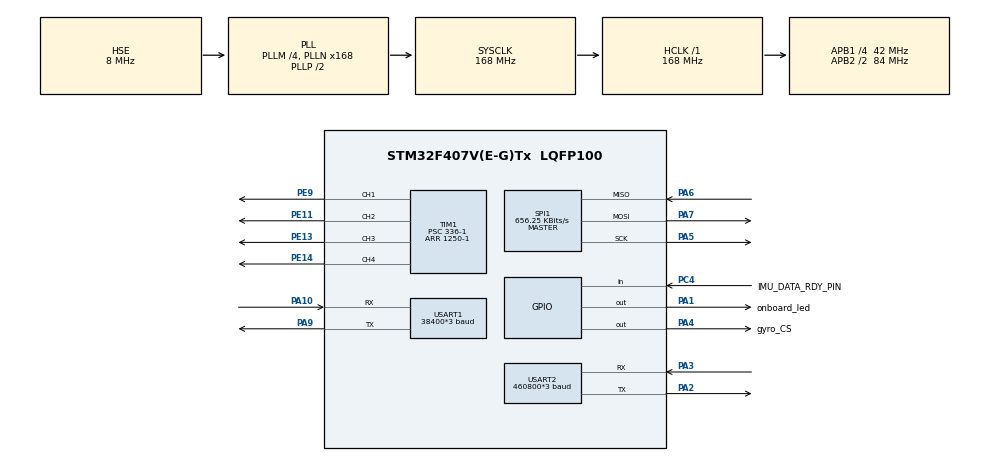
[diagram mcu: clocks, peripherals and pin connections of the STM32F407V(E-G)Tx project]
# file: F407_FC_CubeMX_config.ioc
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Dma.Request0=SPI1_RX
Dma.Request1=SPI1_TX
Dma.Request2=USART1_TX
Dma.SPI1_RX.0.Direction=DMA_PERIPH_TO_MEMORY
Dma.SPI1_RX.0.FIFOMode=DMA_FIFOMODE_DISABLE
Dma.SPI1_RX.0.Instance=DMA2_Stream2
Dma.SPI1_RX.0.MemDataAlignment=DMA_MDATAALIGN_BYTE
Dma.SPI1_RX.0.MemInc=DMA_MINC_ENABLE
Dma.SPI1_RX.0.Mode=DMA_NORMAL
Dma.SPI1_RX.0.PeriphDataAlignment=DMA_PDATAALIGN_BYTE
Dma.SPI1_RX.0.PeriphInc=DMA_PINC_DISABLE
Dma.SPI1_RX.0.Priority=DMA_PRIORITY_LOW
Dma.SPI1_TX.1.Direction=DMA_MEMORY_TO_PERIPH
Dma.SPI1_TX.1.FIFOMode=DMA_FIFOMODE_DISABLE
Dma.SPI1_TX.1.Instance=DMA2_Stream3
Dma.SPI1_TX.1.MemDataAlignment=DMA_MDATAALIGN_BYTE
Dma.SPI1_TX.1.MemInc=DMA_MINC_ENABLE
Dma.SPI1_TX.1.Mode=DMA_NORMAL
Dma.SPI1_TX.1.PeriphDataAlignment=DMA_PDATAALIGN_BYTE
Dma.SPI1_TX.1.PeriphInc=DMA_PINC_DISABLE
Dma.SPI1_TX.1.Priority=DMA_PRIORITY_LOW
Dma.USART1_TX.2.Direction=DMA_MEMORY_TO_PERIPH
Dma.USART1_TX.2.FIFOMode=DMA_FIFOMODE_DISABLE
Dma.USART1_TX.2.Instance=DMA2_Stream7
Dma.USART1_TX.2.MemDataAlignment=DMA_MDATAALIGN_BYTE
Dma.USART1_TX.2.MemInc=DMA_MINC_ENABLE
Dma.USART1_TX.2.Mode=DMA_NORMAL
Dma.USART1_TX.2.PeriphDataAlignment=DMA_PDATAALIGN_BYTE
Dma.USART1_TX.2.PeriphInc=DMA_PINC_DISABLE
Dma.USART1_TX.2.Priority=DMA_PRIORITY_LOW
Mcu.Family=STM32F4
Mcu.Name=STM32F407V(E-G)Tx
Mcu.Package=LQFP100
NVIC.DMA2_Stream2_IRQn=true\:0\:0\:false\:false\:true\:false\:true\:true
NVIC.DMA2_Stream3_IRQn=true\:0\:0\:false\:false\:true\:false\:true\:true
NVIC.DMA2_Stream7_IRQn=true\:0\:0\:false\:false\:true\:false\:true\:true
NVIC.PriorityGroup=NVIC_PRIORITYGROUP_4
NVIC.SPI1_IRQn=true\:0\:0\:false\:false\:true\:true\:true\:true
NVIC.TIM6_DAC_IRQn=true\:0\:0\:false\:false\:true\:true\:true\:true
NVIC.TIM7_IRQn=true\:0\:0\:false\:false\:true\:true\:true\:true
NVIC.USART2_IRQn=true\:0\:0\:false\:false\:true\:true\:true\:true
PA1.GPIO_Label=onboard_led
PA1.GPIO_PuPd=GPIO_PULLUP
PA1.PinState=GPIO_PIN_SET
PA1.Signal=GPIO_Output
PA10.Mode=Asynchronous
PA10.Signal=USART1_RX
PA13.Mode=Serial_Wire
PA13.Signal=SYS_JTMS-SWDIO
PA14.Mode=Serial_Wire
PA14.Signal=SYS_JTCK-SWCLK
PA2.Mode=Asynchronous
PA2.Signal=USART2_TX
PA3.Mode=Asynchronous
PA3.Signal=USART2_RX
PA4.GPIO_Label=gyro_CS
PA4.PinState=GPIO_PIN_SET
PA4.Signal=GPIO_Output
PA5.Mode=Full_Duplex_Master
PA5.Signal=SPI1_SCK
PA6.Mode=Full_Duplex_Master
PA6.Signal=SPI1_MISO
PA7.Mode=Full_Duplex_Master
PA7.Signal=SPI1_MOSI
PA9.Mode=Asynchronous
PA9.Signal=USART1_TX
PC14-OSC32_IN.Mode=LSE-External-Oscillator
PC14-OSC32_IN.Signal=RCC_OSC32_IN
PC15-OSC32_OUT.Mode=LSE-External-Oscillator
PC15-OSC32_OUT.Signal=RCC_OSC32_OUT
PC4.GPIO_Label=IMU_DATA_RDY_PIN
PC4.Signal=GPIO_Input
PE11.Signal=S_TIM1_CH2
PE13.Signal=S_TIM1_CH3
PE14.Signal=S_TIM1_CH4
PE9.Signal=S_TIM1_CH1
PH0-OSC_IN.Mode=HSE-External-Oscillator
PH0-OSC_IN.Signal=RCC_OSC_IN
PH1-OSC_OUT.Mode=HSE-External-Oscillator
PH1-OSC_OUT.Signal=RCC_OSC_OUT
ProjectManager.HeapSize=0x200
ProjectManager.StackSize=0x400
ProjectManager.TargetToolchain=CMake
RCC.48MHZClocksFreq_Value=84000000
RCC.AHBFreq_Value=168000000
RCC.APB1CLKDivider=RCC_HCLK_DIV4
RCC.APB1Freq_Value=42000000
RCC.APB1TimFreq_Value=84000000
RCC.APB2CLKDivider=RCC_HCLK_DIV2
RCC.APB2Freq_Value=84000000
RCC.APB2TimFreq_Value=168000000
RCC.CortexFreq_Value=168000000
RCC.HCLKFreq_Value=168000000
RCC.HSE_VALUE=8000000
RCC.HSI_VALUE=16000000
RCC.PLLM=4
RCC.PLLN=168
RCC.PLLSourceVirtual=RCC_PLLSOURCE_HSE
RCC.SYSCLKFreq_VALUE=168000000
RCC.SYSCLKSource=RCC_SYSCLKSOURCE_PLLCLK
RCC.VCOOutputFreq_Value=336000000
SH.S_TIM1_CH1.0=TIM1_CH1,PWM Generation1 CH1
SH.S_TIM1_CH2.0=TIM1_CH2,PWM Generation2 CH2
SH.S_TIM1_CH3.0=TIM1_CH3,PWM Generation3 CH3
SH.S_TIM1_CH4.0=TIM1_CH4,PWM Generation4 CH4
SPI1.BaudRatePrescaler=SPI_BAUDRATEPRESCALER_128
SPI1.CalculateBaudRate=656.25 KBits/s
SPI1.Direction=SPI_DIRECTION_2LINES
SPI1.Mode=SPI_MODE_MASTER
SPI1.TIMode=SPI_TIMODE_DISABLE
SPI1.VirtualType=VM_MASTER
TIM1.Channel-PWM\ Generation1\ CH1=TIM_CHANNEL_1
TIM1.Channel-PWM\ Generation2\ CH2=TIM_CHANNEL_2
TIM1.Channel-PWM\ Generation3\ CH3=TIM_CHANNEL_3
TIM1.Channel-PWM\ Generation4\ CH4=TIM_CHANNEL_4
TIM1.Period=1250-1
TIM1.Prescaler=336-1
TIM1.Pulse-PWM\ Generation1\ CH1=500
TIM1.Pulse-PWM\ Generation2\ CH2=500
TIM1.Pulse-PWM\ Generation3\ CH3=500
TIM1.Pulse-PWM\ Generation4\ CH4=500
TIM6.Period=10000-1
TIM6.Prescaler=8400-1
TIM7.Period=52500-1
TIM7.Prescaler=4-1
USART1.BaudRate=38400*3
USART1.VirtualMode=VM_ASYNC
USART2.BaudRate=460800*3
USART2.VirtualMode=VM_ASYNC
VP_TIM1_VS_ClockSourceINT.Mode=Internal
VP_TIM6_VS_ClockSourceINT.Mode=Enable_Timer
VP_TIM7_VS_ClockSourceINT.Mode=Enable_Timer
board=custom

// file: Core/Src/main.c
/* USER CODE BEGIN Header */
/**
 ******************************************************************************
 * @file           : main.c
 * @brief          : Main program body
 ******************************************************************************
 * @attention
 *
 * Copyright (c) 2023 STMicroelectronics.
 * All rights reserved.
 *
 * This software is licensed under terms that can be found in the LICENSE file
 * in the root directory of this software component.
 * If no LICENSE file comes with this software, it is provided AS-IS.
 *
 ******************************************************************************
 */
/* USER CODE END Header */
#include "main.h"
#include "dma.h"
#include "spi.h"
#include "tim.h"
#include "usart.h"
#include "gpio.h"

/* USER CODE BEGIN Includes */

#include "global.h"
#include "motors.h"
#include "security.h"
#include "transmission.h"
#include "control.h"
#include "debug.h"
#include "imu.h"
#include "interrupt.h"

/* USER CODE END Includes */

void SystemClock_Config(void);

int main(void)
{

  /* USER CODE BEGIN 1 */
  debug = true;
  /* USER CODE END 1 */

  /* MCU Configuration--------------------------------------------------------*/

  /* Reset of all peripherals, Initializes the Flash interface and the Systick. */
  HAL_Init();

  /* Configure the system clock */
  SystemClock_Config();

  /* Initialize all configured peripherals */
  MX_GPIO_Init();
  MX_DMA_Init();
  MX_TIM1_Init();
  MX_SPI1_Init();
  MX_TIM7_Init();
  MX_USART1_UART_Init();
  MX_USART2_UART_Init();
  MX_TIM6_Init();
  /* USER CODE BEGIN 2 */

  print_to_console("\nstarting ...\n", 14);

  // ESC_init();

  IMU_init();
  HAL_TIM_Base_Start_IT(&htim6); // 1Hz IMU_get_datas loop

  // boucle qui attend STATE remote

  // start_IMU_routine();
  // start_remote_routine();
  // start_control_loop();

  /* USER CODE END 2 */

  /* Infinite loop */
  while (1)
  {

  }
}

void SystemClock_Config(void)
{
  RCC_OscInitTypeDef RCC_OscInitStruct = {0};
  RCC_ClkInitTypeDef RCC_ClkInitStruct = {0};

  /** Configure the main internal regulator output voltage
  */
  __HAL_RCC_PWR_CLK_ENABLE();
  __HAL_PWR_VOLTAGESCALING_CONFIG(PWR_REGULATOR_VOLTAGE_SCALE1);

  /** Initializes the RCC Oscillators according to the specified parameters
  * in the RCC_OscInitTypeDef structure.
  */
  RCC_OscInitStruct.OscillatorType = RCC_OSCILLATORTYPE_HSE;
  RCC_OscInitStruct.HSEState = RCC_HSE_ON;
  RCC_OscInitStruct.PLL.PLLState = RCC_PLL_ON;
  RCC_OscInitStruct.PLL.PLLSource = RCC_PLLSOURCE_HSE;
  RCC_OscInitStruct.PLL.PLLM = 4;
  RCC_OscInitStruct.PLL.PLLN = 168;
  RCC_OscInitStruct.PLL.PLLP = RCC_PLLP_DIV2;
  RCC_OscInitStruct.PLL.PLLQ = 4;
  if (HAL_RCC_OscConfig(&RCC_OscInitStruct) != HAL_OK)
  {
    Error_Handler();
  }

  /** Initializes the CPU, AHB and APB buses clocks
  */
  RCC_ClkInitStruct.ClockType = RCC_CLOCKTYPE_HCLK|RCC_CLOCKTYPE_SYSCLK
                              |RCC_CLOCKTYPE_PCLK1|RCC_CLOCKTYPE_PCLK2;
  RCC_ClkInitStruct.SYSCLKSource = RCC_SYSCLKSOURCE_PLLCLK;
  RCC_ClkInitStruct.AHBCLKDivider = RCC_SYSCLK_DIV1;
  RCC_ClkInitStruct.APB1CLKDivider = RCC_HCLK_DIV4;
  RCC_ClkInitStruct.APB2CLKDivider = RCC_HCLK_DIV2;

  if (HAL_RCC_ClockConfig(&RCC_ClkInitStruct, FLASH_LATENCY_5) != HAL_OK)
  {
    Error_Handler();
  }
}

void Error_Handler(void)
{
  __disable_irq();
  while (1)
  {
  }
}
